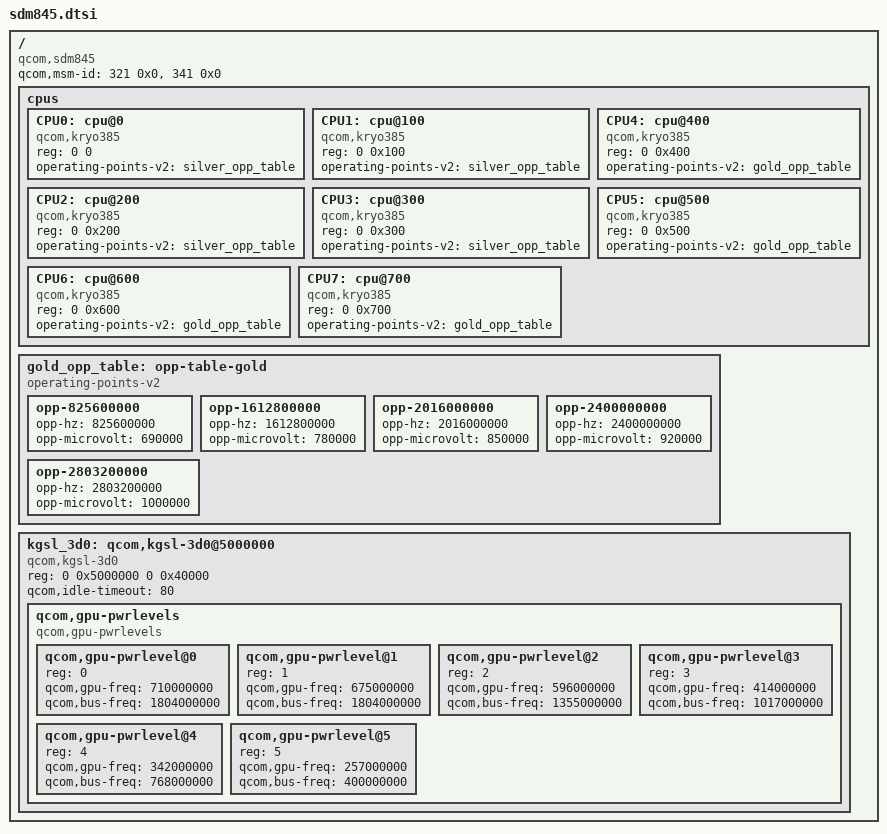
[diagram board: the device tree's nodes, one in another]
// SPDX-License-Identifier: GPL-2.0
/*
 * Qualcomm SDM845 (Snapdragon 845) Device Tree Source
 * Reference: POCOPHONE F1 / Xiaomi Mi 8 (Beryllium / Dipper)
 * 10nm LPP Kryo 385 Architecture
 * Source: MiCode/Xiaomi_Kernel_OpenSource (dipper-o-oss)
 */

/ {
	compatible = "qcom,sdm845";
	qcom,msm-id = <321 0x0>, <341 0x0>;

	cpus {
		#address-cells = <2>;
		#size-cells = <0>;

		/* Silver Cluster: 4x Kryo 385 Silver (Cortex-A55 @ 1.77 GHz) */
		CPU0: cpu@0 { device_type = "cpu"; compatible = "qcom,kryo385"; reg = <0 0>; operating-points-v2 = <&silver_opp_table>; };
		CPU1: cpu@100 { device_type = "cpu"; compatible = "qcom,kryo385"; reg = <0 0x100>; operating-points-v2 = <&silver_opp_table>; };
		CPU2: cpu@200 { device_type = "cpu"; compatible = "qcom,kryo385"; reg = <0 0x200>; operating-points-v2 = <&silver_opp_table>; };
		CPU3: cpu@300 { device_type = "cpu"; compatible = "qcom,kryo385"; reg = <0 0x300>; operating-points-v2 = <&silver_opp_table>; };

		/* Gold Cluster: 4x Kryo 385 Gold (Cortex-A75 @ 2.80 GHz) */
		CPU4: cpu@400 { device_type = "cpu"; compatible = "qcom,kryo385"; reg = <0 0x400>; operating-points-v2 = <&gold_opp_table>; };
		CPU5: cpu@500 { device_type = "cpu"; compatible = "qcom,kryo385"; reg = <0 0x500>; operating-points-v2 = <&gold_opp_table>; };
		CPU6: cpu@600 { device_type = "cpu"; compatible = "qcom,kryo385"; reg = <0 0x600>; operating-points-v2 = <&gold_opp_table>; };
		CPU7: cpu@700 { device_type = "cpu"; compatible = "qcom,kryo385"; reg = <0 0x700>; operating-points-v2 = <&gold_opp_table>; };
	};

	gold_opp_table: opp-table-gold {
		compatible = "operating-points-v2";
		opp-825600000  { opp-hz = /bits/ 64 <825600000>;  opp-microvolt = <690000>; };
		opp-1612800000 { opp-hz = /bits/ 64 <1612800000>; opp-microvolt = <780000>; };
		opp-2016000000 { opp-hz = /bits/ 64 <2016000000>; opp-microvolt = <850000>; };
		opp-2400000000 { opp-hz = /bits/ 64 <2400000000>; opp-microvolt = <920000>; };
		opp-2803200000 { opp-hz = /bits/ 64 <2803200000>; opp-microvolt = <1000000>; };
	};

	/* Adreno 630 GPU */
	kgsl_3d0: qcom,kgsl-3d0@5000000 {
		compatible = "qcom,kgsl-3d0", "qcom,kgsl-3d";
		reg = <0 0x5000000 0 0x40000>;
		qcom,idle-timeout = <80>;

		qcom,gpu-pwrlevels {
			#address-cells = <1>;
			#size-cells = <0>;
			compatible = "qcom,gpu-pwrlevels";

			qcom,gpu-pwrlevel@0 { reg = <0>; qcom,gpu-freq = <710000000>; qcom,bus-freq = <1804000000>; };
			qcom,gpu-pwrlevel@1 { reg = <1>; qcom,gpu-freq = <675000000>; qcom,bus-freq = <1804000000>; };
			qcom,gpu-pwrlevel@2 { reg = <2>; qcom,gpu-freq = <596000000>; qcom,bus-freq = <1355000000>; };
			qcom,gpu-pwrlevel@3 { reg = <3>; qcom,gpu-freq = <414000000>; qcom,bus-freq = <1017000000>; };
			qcom,gpu-pwrlevel@4 { reg = <4>; qcom,gpu-freq = <342000000>; qcom,bus-freq = <768000000>; };
			qcom,gpu-pwrlevel@5 { reg = <5>; qcom,gpu-freq = <257000000>; qcom,bus-freq = <400000000>; };
		};
	};
};
